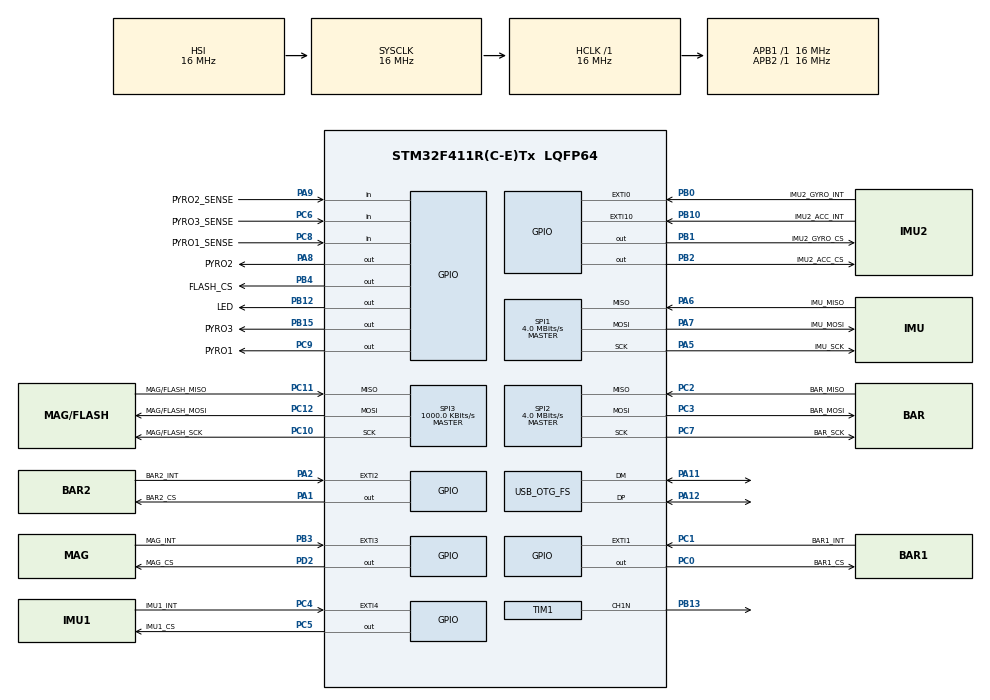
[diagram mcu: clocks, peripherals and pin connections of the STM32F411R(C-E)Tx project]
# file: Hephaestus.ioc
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FREERTOS.Tasks01=defaultTask,24,128,StartDefaultTask,Default,NULL,Dynamic,NULL,NULL
Mcu.Family=STM32F4
Mcu.Name=STM32F411R(C-E)Tx
Mcu.Package=LQFP64
NVIC.OTG_FS_IRQn=true\:5\:0\:false\:false\:true\:true\:false\:true\:true
NVIC.PriorityGroup=NVIC_PRIORITYGROUP_4
NVIC.TIM2_IRQn=true\:15\:0\:false\:false\:true\:false\:false\:true\:true
NVIC.TimeBase=TIM2_IRQn
NVIC.TimeBaseIP=TIM2
PA1.GPIO_Label=BAR2_CS
PA1.Signal=GPIO_Output
PA11.Mode=Device_Only
PA11.Signal=USB_OTG_FS_DM
PA12.Mode=Device_Only
PA12.Signal=USB_OTG_FS_DP
PA13.GPIO_Label=SWDIO
PA13.Mode=Serial_Wire
PA13.Signal=SYS_JTMS-SWDIO
PA14.GPIO_Label=SWCLK
PA14.Mode=Serial_Wire
PA14.Signal=SYS_JTCK-SWCLK
PA2.GPIO_Label=BAR2_INT
PA2.Signal=GPXTI2
PA5.GPIO_Label=IMU_SCK
PA5.Mode=Full_Duplex_Master
PA5.Signal=SPI1_SCK
PA6.GPIO_Label=IMU_MISO
PA6.Mode=Full_Duplex_Master
PA6.Signal=SPI1_MISO
PA7.GPIO_Label=IMU_MOSI
PA7.Mode=Full_Duplex_Master
PA7.Signal=SPI1_MOSI
PA8.GPIO_Label=PYRO2
PA8.Signal=GPIO_Output
PA9.GPIO_Label=PYRO2_SENSE
PA9.Signal=GPIO_Input
PB0.GPIO_Label=IMU2_GYRO_INT
PB0.Signal=GPXTI0
PB1.GPIO_Label=IMU2_GYRO_CS
PB1.Signal=GPIO_Output
PB10.GPIO_Label=IMU2_ACC_INT
PB10.Signal=GPXTI10
PB12.GPIO_Label=LED
PB12.Signal=GPIO_Output
PB13.Mode=PWM Generation1 CH1N
PB13.Signal=TIM1_CH1N
PB15.GPIO_Label=PYRO3
PB15.Signal=GPIO_Output
PB2.GPIO_Label=IMU2_ACC_CS
PB2.Signal=GPIO_Output
PB3.GPIO_Label=MAG_INT
PB3.Signal=GPXTI3
PB4.GPIO_Label=FLASH_CS
PB4.Signal=GPIO_Output
PC0.GPIO_Label=BAR1_CS
PC0.Signal=GPIO_Output
PC1.GPIO_Label=BAR1_INT
PC1.Signal=GPXTI1
PC10.GPIO_Label=MAG/FLASH_SCK
PC10.Mode=Full_Duplex_Master
PC10.Signal=SPI3_SCK
PC11.GPIO_Label=MAG/FLASH_MISO
PC11.Mode=Full_Duplex_Master
PC11.Signal=SPI3_MISO
PC12.GPIO_Label=MAG/FLASH_MOSI
PC12.Mode=Full_Duplex_Master
PC12.Signal=SPI3_MOSI
PC2.GPIO_Label=BAR_MISO
PC2.Mode=Full_Duplex_Master
PC2.Signal=SPI2_MISO
PC3.GPIO_Label=BAR_MOSI
PC3.Mode=Full_Duplex_Master
PC3.Signal=SPI2_MOSI
PC4.GPIO_Label=IMU1_INT
PC4.Signal=GPXTI4
PC5.GPIO_Label=IMU1_CS
PC5.Signal=GPIO_Output
PC6.GPIO_Label=PYRO3_SENSE
PC6.Signal=GPIO_Input
PC7.GPIO_Label=BAR_SCK
PC7.Mode=Full_Duplex_Master
PC7.Signal=SPI2_SCK
PC8.GPIO_Label=PYRO1_SENSE
PC8.Signal=GPIO_Input
PC9.GPIO_Label=PYRO1
PC9.Signal=GPIO_Output
PD2.GPIO_Label=MAG_CS
PD2.Signal=GPIO_Output
PH0\ -\ OSC_IN.Mode=HSE-External-Oscillator
PH0\ -\ OSC_IN.Signal=RCC_OSC_IN
PH1\ -\ OSC_OUT.Mode=HSE-External-Oscillator
PH1\ -\ OSC_OUT.Signal=RCC_OSC_OUT
ProjectManager.HeapSize=0x200
ProjectManager.StackSize=0x400
ProjectManager.TargetToolchain=CMake
RCC.48MHZClocksFreq_Value=48000000
RCC.AHBFreq_Value=16000000
RCC.APB1Freq_Value=16000000
RCC.APB2Freq_Value=16000000
RCC.CortexFreq_Value=16000000
RCC.HSE_VALUE=25000000
RCC.HSI_VALUE=16000000
RCC.LSE_VALUE=32768
RCC.PLLM=15
RCC.PLLN=144
RCC.PLLQ=5
RCC.SYSCLKFreq_VALUE=16000000
RCC.VCOOutputFreq_Value=240000000
SPI1.BaudRatePrescaler=SPI_BAUDRATEPRESCALER_4
SPI1.CalculateBaudRate=4.0 MBits/s
SPI1.Direction=SPI_DIRECTION_2LINES
SPI1.Mode=SPI_MODE_MASTER
SPI1.VirtualType=VM_MASTER
SPI2.BaudRatePrescaler=SPI_BAUDRATEPRESCALER_4
SPI2.CalculateBaudRate=4.0 MBits/s
SPI2.Direction=SPI_DIRECTION_2LINES
SPI2.Mode=SPI_MODE_MASTER
SPI2.VirtualType=VM_MASTER
SPI3.BaudRatePrescaler=SPI_BAUDRATEPRESCALER_16
SPI3.CalculateBaudRate=1000.0 KBits/s
SPI3.Direction=SPI_DIRECTION_2LINES
SPI3.Mode=SPI_MODE_MASTER
SPI3.VirtualType=VM_MASTER
TIM1.Channel-PWM\ Generation1\ CH1N=TIM_CHANNEL_1
TIM1.Period=250-1
TIM1.Prescaler=16-1
TIM5.Period=3599999999
TIM5.Prescaler=16-1
USB_DEVICE.CLASS_NAME_FS=CDC
USB_DEVICE.VirtualMode=Cdc
USB_DEVICE.VirtualModeFS=Cdc_FS
USB_OTG_FS.VirtualMode=Device_Only
VP_CRC_VS_CRC.Mode=CRC_Activate
VP_FREERTOS_VS_CMSIS_V2.Mode=CMSIS_V2
VP_SYS_VS_tim2.Mode=TIM2
VP_TIM1_VS_ClockSourceINT.Mode=Internal
VP_TIM5_VS_ClockSourceINT.Mode=Internal
VP_USB_DEVICE_VS_USB_DEVICE_CDC_FS.Mode=CDC_FS
board=custom

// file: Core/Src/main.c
/* USER CODE BEGIN Header */
/**
  ******************************************************************************
  * @file           : main.c
  * @brief          : Main program body
  ******************************************************************************
  * @attention
  *
  * Copyright (c) 2025 STMicroelectronics.
  * All rights reserved.
  *
  * This software is licensed under terms that can be found in the LICENSE file
  * in the root directory of this software component.
  * If no LICENSE file comes with this software, it is provided AS-IS.
  *
  ******************************************************************************
  */
/* USER CODE END Header */
#include "main.h"
#include "cmsis_os.h"
#include "usb_device.h"

/* USER CODE BEGIN Includes */
/* const int __attribute__((used)) uxTopUsedPriority = configMAX_PRIORITIES - 1; */
#include "device-init.h"
const volatile UBaseType_t uxTopUsedPriority = 15;

#include "usb_device.h"
#include "usbd_cdc_if.h"
/* USER CODE END Includes */

CRC_HandleTypeDef hcrc;

SPI_HandleTypeDef hspi1;
SPI_HandleTypeDef hspi2;
SPI_HandleTypeDef hspi3;

TIM_HandleTypeDef htim1;
TIM_HandleTypeDef htim5;

/* Definitions for defaultTask */
osThreadId_t defaultTaskHandle;
const osThreadAttr_t defaultTask_attributes = {
  .name = "defaultTask",
  .stack_size = 1024 * 4,
  .priority = (osPriority_t) osPriorityNormal,
};
/* USER CODE BEGIN PV */
/// For openocd, it is an official workaround for the following
/// Error: FreeRTOS: uxTopUsedPriority is not defined, consult the OpenOCD manual for a work-around
/* USER CODE END PV */

void SystemClock_Config(void);
static void MX_GPIO_Init(void);
static void MX_SPI1_Init(void);
static void MX_SPI2_Init(void);
static void MX_SPI3_Init(void);
static void MX_CRC_Init(void);
static void MX_TIM1_Init(void);
static void MX_TIM5_Init(void);
void StartDefaultTask(void *argument);

int main(void)
{

  /* USER CODE BEGIN 1 */
  // Prevents compiler from stripping this out
  (void)uxTopUsedPriority;
  /* USER CODE END 1 */

  /* MCU Configuration--------------------------------------------------------*/

  /* Reset of all peripherals, Initializes the Flash interface and the Systick. */
  HAL_Init();

  /* Configure the system clock */
  SystemClock_Config();

  /* Initialize all configured peripherals */
  MX_GPIO_Init();
  MX_SPI1_Init();
  MX_SPI2_Init();
  MX_SPI3_Init();
  MX_CRC_Init();
  MX_TIM1_Init();
  MX_TIM5_Init();

  /* Init scheduler */
  osKernelInitialize();

  /* Create the thread(s) */
  /* creation of defaultTask */
  defaultTaskHandle = osThreadNew(StartDefaultTask, NULL, &defaultTask_attributes);

  /* Start scheduler */
  osKernelStart();

  /* We should never get here as control is now taken by the scheduler */
}

void SystemClock_Config(void)
{
  RCC_OscInitTypeDef RCC_OscInitStruct = {0};
  RCC_ClkInitTypeDef RCC_ClkInitStruct = {0};

  /** Configure the main internal regulator output voltage
  */
  __HAL_RCC_PWR_CLK_ENABLE();
  __HAL_PWR_VOLTAGESCALING_CONFIG(PWR_REGULATOR_VOLTAGE_SCALE1);

  /** Initializes the RCC Oscillators according to the specified parameters
  * in the RCC_OscInitTypeDef structure.
  */
  RCC_OscInitStruct.OscillatorType = RCC_OSCILLATORTYPE_HSI|RCC_OSCILLATORTYPE_HSE;
  RCC_OscInitStruct.HSEState = RCC_HSE_ON;
  RCC_OscInitStruct.HSIState = RCC_HSI_ON;
  RCC_OscInitStruct.HSICalibrationValue = RCC_HSICALIBRATION_DEFAULT;
  RCC_OscInitStruct.PLL.PLLState = RCC_PLL_ON;
  RCC_OscInitStruct.PLL.PLLSource = RCC_PLLSOURCE_HSE;
  RCC_OscInitStruct.PLL.PLLM = 15;
  RCC_OscInitStruct.PLL.PLLN = 144;
  RCC_OscInitStruct.PLL.PLLP = RCC_PLLP_DIV2;
  RCC_OscInitStruct.PLL.PLLQ = 5;
  if (HAL_RCC_OscConfig(&RCC_OscInitStruct) != HAL_OK)
  {
    Error_Handler();
  }

  /** Initializes the CPU, AHB and APB buses clocks
  */
  RCC_ClkInitStruct.ClockType = RCC_CLOCKTYPE_HCLK|RCC_CLOCKTYPE_SYSCLK
                              |RCC_CLOCKTYPE_PCLK1|RCC_CLOCKTYPE_PCLK2;
  RCC_ClkInitStruct.SYSCLKSource = RCC_SYSCLKSOURCE_HSI;
  RCC_ClkInitStruct.AHBCLKDivider = RCC_SYSCLK_DIV1;
  RCC_ClkInitStruct.APB1CLKDivider = RCC_HCLK_DIV1;
  RCC_ClkInitStruct.APB2CLKDivider = RCC_HCLK_DIV1;

  if (HAL_RCC_ClockConfig(&RCC_ClkInitStruct, FLASH_LATENCY_0) != HAL_OK)
  {
    Error_Handler();
  }
}

static void MX_CRC_Init(void)
{

  hcrc.Instance = CRC;
  if (HAL_CRC_Init(&hcrc) != HAL_OK)
  {
    Error_Handler();
  }

}

static void MX_SPI1_Init(void)
{

  /* SPI1 parameter configuration*/
  hspi1.Instance = SPI1;
  hspi1.Init.Mode = SPI_MODE_MASTER;
  hspi1.Init.Direction = SPI_DIRECTION_2LINES;
  hspi1.Init.DataSize = SPI_DATASIZE_8BIT;
  hspi1.Init.CLKPolarity = SPI_POLARITY_LOW;
  hspi1.Init.CLKPhase = SPI_PHASE_1EDGE;
  hspi1.Init.NSS = SPI_NSS_SOFT;
  hspi1.Init.BaudRatePrescaler = SPI_BAUDRATEPRESCALER_4;
  hspi1.Init.FirstBit = SPI_FIRSTBIT_MSB;
  hspi1.Init.TIMode = SPI_TIMODE_DISABLE;
  hspi1.Init.CRCCalculation = SPI_CRCCALCULATION_DISABLE;
  hspi1.Init.CRCPolynomial = 10;
  if (HAL_SPI_Init(&hspi1) != HAL_OK)
  {
    Error_Handler();
  }

}

static void MX_SPI2_Init(void)
{

  /* SPI2 parameter configuration*/
  hspi2.Instance = SPI2;
  hspi2.Init.Mode = SPI_MODE_MASTER;
  hspi2.Init.Direction = SPI_DIRECTION_2LINES;
  hspi2.Init.DataSize = SPI_DATASIZE_8BIT;
  hspi2.Init.CLKPolarity = SPI_POLARITY_LOW;
  hspi2.Init.CLKPhase = SPI_PHASE_1EDGE;
  hspi2.Init.NSS = SPI_NSS_SOFT;
  hspi2.Init.BaudRatePrescaler = SPI_BAUDRATEPRESCALER_4;
  hspi2.Init.FirstBit = SPI_FIRSTBIT_MSB;
  hspi2.Init.TIMode = SPI_TIMODE_DISABLE;
  hspi2.Init.CRCCalculation = SPI_CRCCALCULATION_DISABLE;
  hspi2.Init.CRCPolynomial = 10;
  if (HAL_SPI_Init(&hspi2) != HAL_OK)
  {
    Error_Handler();
  }

}

static void MX_SPI3_Init(void)
{

  /* SPI3 parameter configuration*/
  hspi3.Instance = SPI3;
  hspi3.Init.Mode = SPI_MODE_MASTER;
  hspi3.Init.Direction = SPI_DIRECTION_2LINES;
  hspi3.Init.DataSize = SPI_DATASIZE_8BIT;
  hspi3.Init.CLKPolarity = SPI_POLARITY_LOW;
  hspi3.Init.CLKPhase = SPI_PHASE_1EDGE;
  hspi3.Init.NSS = SPI_NSS_SOFT;
  hspi3.Init.BaudRatePrescaler = SPI_BAUDRATEPRESCALER_16;
  hspi3.Init.FirstBit = SPI_FIRSTBIT_MSB;
  hspi3.Init.TIMode = SPI_TIMODE_DISABLE;
  hspi3.Init.CRCCalculation = SPI_CRCCALCULATION_DISABLE;
  hspi3.Init.CRCPolynomial = 10;
  if (HAL_SPI_Init(&hspi3) != HAL_OK)
  {
    Error_Handler();
  }

}

static void MX_TIM1_Init(void)
{

  TIM_ClockConfigTypeDef sClockSourceConfig = {0};
  TIM_MasterConfigTypeDef sMasterConfig = {0};
  TIM_OC_InitTypeDef sConfigOC = {0};
  TIM_BreakDeadTimeConfigTypeDef sBreakDeadTimeConfig = {0};

  htim1.Instance = TIM1;
  htim1.Init.Prescaler = 16-1;
  htim1.Init.CounterMode = TIM_COUNTERMODE_UP;
  htim1.Init.Period = 250-1;
  htim1.Init.ClockDivision = TIM_CLOCKDIVISION_DIV1;
  htim1.Init.RepetitionCounter = 0;
  htim1.Init.AutoReloadPreload = TIM_AUTORELOAD_PRELOAD_DISABLE;
  if (HAL_TIM_Base_Init(&htim1) != HAL_OK)
  {
    Error_Handler();
  }
  sClockSourceConfig.ClockSource = TIM_CLOCKSOURCE_INTERNAL;
  if (HAL_TIM_ConfigClockSource(&htim1, &sClockSourceConfig) != HAL_OK)
  {
    Error_Handler();
  }
  if (HAL_TIM_PWM_Init(&htim1) != HAL_OK)
  {
    Error_Handler();
  }
  sMasterConfig.MasterOutputTrigger = TIM_TRGO_RESET;
  sMasterConfig.MasterSlaveMode = TIM_MASTERSLAVEMODE_DISABLE;
  if (HAL_TIMEx_MasterConfigSynchronization(&htim1, &sMasterConfig) != HAL_OK)
  {
    Error_Handler();
  }
  sConfigOC.OCMode = TIM_OCMODE_PWM1;
  sConfigOC.Pulse = 0;
  sConfigOC.OCPolarity = TIM_OCPOLARITY_HIGH;
  sConfigOC.OCNPolarity = TIM_OCNPOLARITY_HIGH;
  sConfigOC.OCFastMode = TIM_OCFAST_DISABLE;
  sConfigOC.OCIdleState = TIM_OCIDLESTATE_RESET;
  sConfigOC.OCNIdleState = TIM_OCNIDLESTATE_RESET;
  if (HAL_TIM_PWM_ConfigChannel(&htim1, &sConfigOC, TIM_CHANNEL_1) != HAL_OK)
  {
    Error_Handler();
  }
  sBreakDeadTimeConfig.OffStateRunMode = TIM_OSSR_DISABLE;
  sBreakDeadTimeConfig.OffStateIDLEMode = TIM_OSSI_DISABLE;
  sBreakDeadTimeConfig.LockLevel = TIM_LOCKLEVEL_OFF;
  sBreakDeadTimeConfig.DeadTime = 0;
  sBreakDeadTimeConfig.BreakState = TIM_BREAK_DISABLE;
  sBreakDeadTimeConfig.BreakPolarity = TIM_BREAKPOLARITY_HIGH;
  sBreakDeadTimeConfig.AutomaticOutput = TIM_AUTOMATICOUTPUT_DISABLE;
  if (HAL_TIMEx_ConfigBreakDeadTime(&htim1, &sBreakDeadTimeConfig) != HAL_OK)
  {
    Error_Handler();
  }
  HAL_TIM_MspPostInit(&htim1);

}

static void MX_TIM5_Init(void)
{

  TIM_ClockConfigTypeDef sClockSourceConfig = {0};
  TIM_MasterConfigTypeDef sMasterConfig = {0};

  htim5.Instance = TIM5;
  htim5.Init.Prescaler = 16-1;
  htim5.Init.CounterMode = TIM_COUNTERMODE_UP;
  htim5.Init.Period = 3599999999;
  htim5.Init.ClockDivision = TIM_CLOCKDIVISION_DIV1;
  htim5.Init.AutoReloadPreload = TIM_AUTORELOAD_PRELOAD_DISABLE;
  if (HAL_TIM_Base_Init(&htim5) != HAL_OK)
  {
    Error_Handler();
  }
  sClockSourceConfig.ClockSource = TIM_CLOCKSOURCE_INTERNAL;
  if (HAL_TIM_ConfigClockSource(&htim5, &sClockSourceConfig) != HAL_OK)
  {
    Error_Handler();
  }
  sMasterConfig.MasterOutputTrigger = TIM_TRGO_RESET;
  sMasterConfig.MasterSlaveMode = TIM_MASTERSLAVEMODE_DISABLE;
  if (HAL_TIMEx_MasterConfigSynchronization(&htim5, &sMasterConfig) != HAL_OK)
  {
    Error_Handler();
  }

}

static void MX_GPIO_Init(void)
{
  GPIO_InitTypeDef GPIO_InitStruct = {0};

  /* GPIO Ports Clock Enable */
  __HAL_RCC_GPIOH_CLK_ENABLE();
  __HAL_RCC_GPIOC_CLK_ENABLE();
  __HAL_RCC_GPIOA_CLK_ENABLE();
  __HAL_RCC_GPIOB_CLK_ENABLE();
  __HAL_RCC_GPIOD_CLK_ENABLE();

  /*Configure GPIO pin Output Level */
  HAL_GPIO_WritePin(GPIOC, BAR1_CS_Pin|IMU1_CS_Pin|PYRO1_Pin, GPIO_PIN_RESET);

  /*Configure GPIO pin Output Level */
  HAL_GPIO_WritePin(GPIOA, BAR2_CS_Pin|PYRO2_Pin, GPIO_PIN_RESET);

  /*Configure GPIO pin Output Level */
  HAL_GPIO_WritePin(GPIOB, IMU2_GYRO_CS_Pin|IMU2_ACC_CS_Pin|LED_Pin|PYRO3_Pin
                          |FLASH_CS_Pin, GPIO_PIN_RESET);

  /*Configure GPIO pin Output Level */
  HAL_GPIO_WritePin(MAG_CS_GPIO_Port, MAG_CS_Pin, GPIO_PIN_RESET);

  /*Configure GPIO pins : BAR1_CS_Pin IMU1_CS_Pin PYRO1_Pin */
  GPIO_InitStruct.Pin = BAR1_CS_Pin|IMU1_CS_Pin|PYRO1_Pin;
  GPIO_InitStruct.Mode = GPIO_MODE_OUTPUT_PP;
  GPIO_InitStruct.Pull = GPIO_NOPULL;
  GPIO_InitStruct.Speed = GPIO_SPEED_FREQ_LOW;
  HAL_GPIO_Init(GPIOC, &GPIO_InitStruct);

  /*Configure GPIO pins : BAR1_INT_Pin IMU1_INT_Pin */
  GPIO_InitStruct.Pin = BAR1_INT_Pin|IMU1_INT_Pin;
  GPIO_InitStruct.Mode = GPIO_MODE_IT_RISING;
  GPIO_InitStruct.Pull = GPIO_NOPULL;
  HAL_GPIO_Init(GPIOC, &GPIO_InitStruct);

  /*Configure GPIO pins : BAR2_CS_Pin PYRO2_Pin */
  GPIO_InitStruct.Pin = BAR2_CS_Pin|PYRO2_Pin;
  GPIO_InitStruct.Mode = GPIO_MODE_OUTPUT_PP;
  GPIO_InitStruct.Pull = GPIO_NOPULL;
  GPIO_InitStruct.Speed = GPIO_SPEED_FREQ_LOW;
  HAL_GPIO_Init(GPIOA, &GPIO_InitStruct);

  /*Configure GPIO pin : BAR2_INT_Pin */
  GPIO_InitStruct.Pin = BAR2_INT_Pin;
  GPIO_InitStruct.Mode = GPIO_MODE_IT_RISING;
  GPIO_InitStruct.Pull = GPIO_NOPULL;
  HAL_GPIO_Init(BAR2_INT_GPIO_Port, &GPIO_InitStruct);

  /*Configure GPIO pins : IMU2_GYRO_INT_Pin IMU2_ACC_INT_Pin MAG_INT_Pin */
  GPIO_InitStruct.Pin = IMU2_GYRO_INT_Pin|IMU2_ACC_INT_Pin|MAG_INT_Pin;
  GPIO_InitStruct.Mode = GPIO_MODE_IT_RISING;
  GPIO_InitStruct.Pull = GPIO_NOPULL;
  HAL_GPIO_Init(GPIOB, &GPIO_InitStruct);

  /*Configure GPIO pins : IMU2_GYRO_CS_Pin IMU2_ACC_CS_Pin LED_Pin PYRO3_Pin
                           FLASH_CS_Pin */
  GPIO_InitStruct.Pin = IMU2_GYRO_CS_Pin|IMU2_ACC_CS_Pin|LED_Pin|PYRO3_Pin
                          |FLASH_CS_Pin;
  GPIO_InitStruct.Mode = GPIO_MODE_OUTPUT_PP;
  GPIO_InitStruct.Pull = GPIO_NOPULL;
  GPIO_InitStruct.Speed = GPIO_SPEED_FREQ_LOW;
  HAL_GPIO_Init(GPIOB, &GPIO_InitStruct);

  /*Configure GPIO pins : PYRO3_SENSE_Pin PYRO1_SENSE_Pin */
  GPIO_InitStruct.Pin = PYRO3_SENSE_Pin|PYRO1_SENSE_Pin;
  GPIO_InitStruct.Mode = GPIO_MODE_INPUT;
  GPIO_InitStruct.Pull = GPIO_NOPULL;
  HAL_GPIO_Init(GPIOC, &GPIO_InitStruct);

  /*Configure GPIO pin : PYRO2_SENSE_Pin */
  GPIO_InitStruct.Pin = PYRO2_SENSE_Pin;
  GPIO_InitStruct.Mode = GPIO_MODE_INPUT;
  GPIO_InitStruct.Pull = GPIO_NOPULL;
  HAL_GPIO_Init(PYRO2_SENSE_GPIO_Port, &GPIO_InitStruct);

  /*Configure GPIO pin : MAG_CS_Pin */
  GPIO_InitStruct.Pin = MAG_CS_Pin;
  GPIO_InitStruct.Mode = GPIO_MODE_OUTPUT_PP;
  GPIO_InitStruct.Pull = GPIO_NOPULL;
  GPIO_InitStruct.Speed = GPIO_SPEED_FREQ_LOW;
  HAL_GPIO_Init(MAG_CS_GPIO_Port, &GPIO_InitStruct);

}

void StartDefaultTask(void *argument)
{
  /* init code for USB_DEVICE */
  MX_USB_DEVICE_Init();
  /* USER CODE BEGIN 5 */
  device_init(&hspi1, &hspi2, &hspi3, &hcrc);
  /* Infinite loop */
  for(;;)
  {
    osDelay(1);
  }
  /* USER CODE END 5 */
}

void HAL_TIM_PeriodElapsedCallback(TIM_HandleTypeDef *htim)
{
  if (htim->Instance == TIM2)
  {
    HAL_IncTick();
  }
  /* USER CODE BEGIN Callback 1 */
  if (htim->Instance == TIM5)
  {
    device_disable_flash();
  }
  /* USER CODE END Callback 1 */
}

void Error_Handler(void)
{
  __disable_irq();
  while (1)
  {
  }
}
